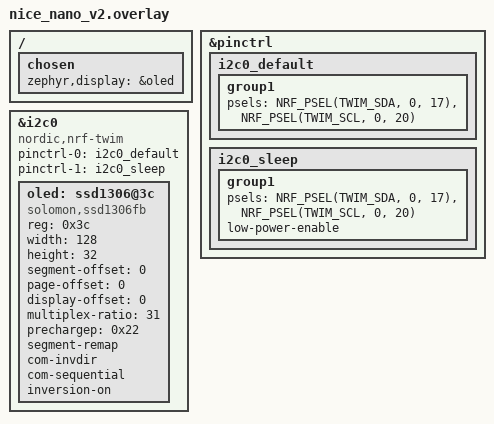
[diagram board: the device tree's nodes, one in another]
/**
 * Generated by Shield Wizard for ZMK
 * Applies to part "right" with controller "nice_nano_v2"
 */

// pin control for i2c0
// - SDA on D2
// - SCL on D3
&pinctrl {
    /* configuration for i2c0 device, default state */
    i2c0_default: i2c0_default {
        group1 {
            psels = <NRF_PSEL(TWIM_SDA, 0, 17)>,
                    <NRF_PSEL(TWIM_SCL, 0, 20)>;
        };
    };
    /* configuration for i2c0 device, sleep state */
    i2c0_sleep: i2c0_sleep {
        group1 {
            psels = <NRF_PSEL(TWIM_SDA, 0, 17)>,
                    <NRF_PSEL(TWIM_SCL, 0, 20)>;
            low-power-enable;
        };
    };
};
&i2c0 {
    compatible = "nordic,nrf-twim";
    status = "okay";
    pinctrl-0 = <&i2c0_default>;
    pinctrl-1 = <&i2c0_sleep>;
    pinctrl-names = "default", "sleep";
    // Left at the 100kHz default. The wizard generated I2C_BITRATE_FAST
    // (400kHz), which many SSD1306 modules cannot hold reliably - corrupted
    // writes show up as scrambled pixels. ZMK's own OLED shields do not
    // raise the bus speed.
};

// devices on i2c0

&i2c0 {
    oled: ssd1306@3c {
        compatible = "solomon,ssd1306fb";
        reg = <0x3c>;
        width = <128>;
        height = <32>;

        segment-offset = <0>;
        page-offset = <0>;
        display-offset = <0>;
        multiplex-ratio = <31>;
        prechargep = <0x22>;
        segment-remap;
        com-invdir;
        com-sequential;
        inversion-on;
    };
};
/ {
    chosen {
        zephyr,display = &oled;
    };
};
